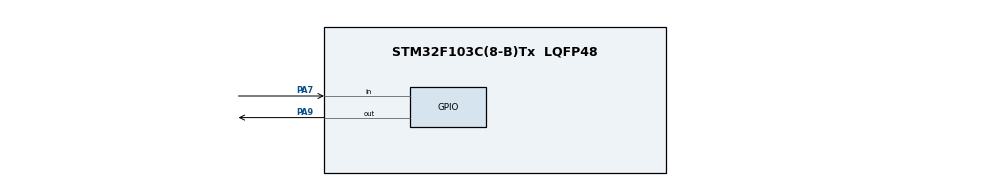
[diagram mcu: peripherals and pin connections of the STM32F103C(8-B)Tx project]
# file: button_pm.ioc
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Mcu.Family=STM32F1
Mcu.Name=STM32F103C(8-B)Tx
Mcu.Package=LQFP48
NVIC.PriorityGroup=NVIC_PRIORITYGROUP_4
NVIC.TIM1_UP_IRQn=true\:0\:0\:false\:false\:true\:true\:true\:true
NVIC.TIM2_IRQn=true\:0\:0\:false\:false\:true\:true\:true\:true
PA13.Mode=Serial_Wire
PA13.Signal=SYS_JTMS-SWDIO
PA14.Mode=Serial_Wire
PA14.Signal=SYS_JTCK-SWCLK
PA7.GPIO_PuPd=GPIO_PULLUP
PA7.Signal=GPIO_Input
PA9.Signal=GPIO_Output
ProjectManager.HeapSize=0x200
ProjectManager.StackSize=0x400
ProjectManager.TargetToolchain=MDK-ARM V5.32
RCC.APB1Freq_Value=8000000
RCC.APB2Freq_Value=8000000
TIM1.Period=9999
TIM1.Prescaler=79
TIM2.Period=999
TIM2.Prescaler=7
VP_TIM1_VS_ClockSourceINT.Mode=Internal
VP_TIM2_VS_ClockSourceINT.Mode=Internal
board=custom

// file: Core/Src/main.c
/* USER CODE BEGIN Header */
/**
  ******************************************************************************
  * @file           : main.c
  * @brief          : Main program body
  ******************************************************************************
  * @attention
  *
  * Copyright (c) 2026 STMicroelectronics.
  * All rights reserved.
  *
  * This software is licensed under terms that can be found in the LICENSE file
  * in the root directory of this software component.
  * If no LICENSE file comes with this software, it is provided AS-IS.
  *
  ******************************************************************************
  */
/* USER CODE END Header */
#include "main.h"

TIM_HandleTypeDef htim1;
TIM_HandleTypeDef htim2;

/* USER CODE BEGIN PV */
uint32_t state=0,blink=0,model=1;
/* USER CODE END PV */

void SystemClock_Config(void);
static void MX_GPIO_Init(void);
static void MX_TIM1_Init(void);
static void MX_TIM2_Init(void);

int main(void)
{

  /* MCU Configuration--------------------------------------------------------*/

  /* Reset of all peripherals, Initializes the Flash interface and the Systick. */
  HAL_Init();

  /* Configure the system clock */
  SystemClock_Config();

  /* Initialize all configured peripherals */
  MX_GPIO_Init();
  MX_TIM1_Init();
  MX_TIM2_Init();
  /* USER CODE BEGIN 2 */
 HAL_TIM_Base_Start_IT(&htim2);
  /* USER CODE END 2 */

  /* Infinite loop */
  /* USER CODE BEGIN WHILE */
  while (1)
  {
		if (model==1)
		{
			if (state==1)
			{
				HAL_GPIO_WritePin(GPIOA,GPIO_PIN_9,GPIO_PIN_SET);
			}
			else HAL_GPIO_WritePin(GPIOA,GPIO_PIN_9,GPIO_PIN_RESET);
		}
		else
		{
			if(blink==1)
			{
				HAL_TIM_Base_Start_IT(&htim1);
			}
			else
			{
				HAL_GPIO_WritePin(GPIOA,GPIO_PIN_9,GPIO_PIN_RESET);
				HAL_TIM_Base_Stop_IT(&htim1);
			}
		}
    /* USER CODE END WHILE */

  }
}

void SystemClock_Config(void)
{
  RCC_OscInitTypeDef RCC_OscInitStruct = {0};
  RCC_ClkInitTypeDef RCC_ClkInitStruct = {0};

  /** Initializes the RCC Oscillators according to the specified parameters
  * in the RCC_OscInitTypeDef structure.
  */
  RCC_OscInitStruct.OscillatorType = RCC_OSCILLATORTYPE_HSI;
  RCC_OscInitStruct.HSIState = RCC_HSI_ON;
  RCC_OscInitStruct.HSICalibrationValue = RCC_HSICALIBRATION_DEFAULT;
  RCC_OscInitStruct.PLL.PLLState = RCC_PLL_NONE;
  if (HAL_RCC_OscConfig(&RCC_OscInitStruct) != HAL_OK)
  {
    Error_Handler();
  }

  /** Initializes the CPU, AHB and APB buses clocks
  */
  RCC_ClkInitStruct.ClockType = RCC_CLOCKTYPE_HCLK|RCC_CLOCKTYPE_SYSCLK
                              |RCC_CLOCKTYPE_PCLK1|RCC_CLOCKTYPE_PCLK2;
  RCC_ClkInitStruct.SYSCLKSource = RCC_SYSCLKSOURCE_HSI;
  RCC_ClkInitStruct.AHBCLKDivider = RCC_SYSCLK_DIV1;
  RCC_ClkInitStruct.APB1CLKDivider = RCC_HCLK_DIV1;
  RCC_ClkInitStruct.APB2CLKDivider = RCC_HCLK_DIV1;

  if (HAL_RCC_ClockConfig(&RCC_ClkInitStruct, FLASH_LATENCY_0) != HAL_OK)
  {
    Error_Handler();
  }
}

static void MX_TIM1_Init(void)
{

  TIM_ClockConfigTypeDef sClockSourceConfig = {0};
  TIM_MasterConfigTypeDef sMasterConfig = {0};

  htim1.Instance = TIM1;
  htim1.Init.Prescaler = 79;
  htim1.Init.CounterMode = TIM_COUNTERMODE_UP;
  htim1.Init.Period = 9999;
  htim1.Init.ClockDivision = TIM_CLOCKDIVISION_DIV1;
  htim1.Init.RepetitionCounter = 0;
  htim1.Init.AutoReloadPreload = TIM_AUTORELOAD_PRELOAD_DISABLE;
  if (HAL_TIM_Base_Init(&htim1) != HAL_OK)
  {
    Error_Handler();
  }
  sClockSourceConfig.ClockSource = TIM_CLOCKSOURCE_INTERNAL;
  if (HAL_TIM_ConfigClockSource(&htim1, &sClockSourceConfig) != HAL_OK)
  {
    Error_Handler();
  }
  sMasterConfig.MasterOutputTrigger = TIM_TRGO_RESET;
  sMasterConfig.MasterSlaveMode = TIM_MASTERSLAVEMODE_DISABLE;
  if (HAL_TIMEx_MasterConfigSynchronization(&htim1, &sMasterConfig) != HAL_OK)
  {
    Error_Handler();
  }

}

static void MX_TIM2_Init(void)
{

  TIM_ClockConfigTypeDef sClockSourceConfig = {0};
  TIM_MasterConfigTypeDef sMasterConfig = {0};

  htim2.Instance = TIM2;
  htim2.Init.Prescaler = 7;
  htim2.Init.CounterMode = TIM_COUNTERMODE_UP;
  htim2.Init.Period = 999;
  htim2.Init.ClockDivision = TIM_CLOCKDIVISION_DIV1;
  htim2.Init.AutoReloadPreload = TIM_AUTORELOAD_PRELOAD_DISABLE;
  if (HAL_TIM_Base_Init(&htim2) != HAL_OK)
  {
    Error_Handler();
  }
  sClockSourceConfig.ClockSource = TIM_CLOCKSOURCE_INTERNAL;
  if (HAL_TIM_ConfigClockSource(&htim2, &sClockSourceConfig) != HAL_OK)
  {
    Error_Handler();
  }
  sMasterConfig.MasterOutputTrigger = TIM_TRGO_RESET;
  sMasterConfig.MasterSlaveMode = TIM_MASTERSLAVEMODE_DISABLE;
  if (HAL_TIMEx_MasterConfigSynchronization(&htim2, &sMasterConfig) != HAL_OK)
  {
    Error_Handler();
  }

}

static void MX_GPIO_Init(void)
{
  GPIO_InitTypeDef GPIO_InitStruct = {0};

  /* GPIO Ports Clock Enable */
  __HAL_RCC_GPIOA_CLK_ENABLE();

  /*Configure GPIO pin Output Level */
  HAL_GPIO_WritePin(GPIOA, GPIO_PIN_9, GPIO_PIN_RESET);

  /*Configure GPIO pin : PA7 */
  GPIO_InitStruct.Pin = GPIO_PIN_7;
  GPIO_InitStruct.Mode = GPIO_MODE_INPUT;
  GPIO_InitStruct.Pull = GPIO_PULLUP;
  HAL_GPIO_Init(GPIOA, &GPIO_InitStruct);

  /*Configure GPIO pin : PA9 */
  GPIO_InitStruct.Pin = GPIO_PIN_9;
  GPIO_InitStruct.Mode = GPIO_MODE_OUTPUT_PP;
  GPIO_InitStruct.Pull = GPIO_NOPULL;
  GPIO_InitStruct.Speed = GPIO_SPEED_FREQ_LOW;
  HAL_GPIO_Init(GPIOA, &GPIO_InitStruct);

}

/* USER CODE BEGIN 4 */
uint32_t count=0;
void HAL_TIM_PeriodElapsedCallback(TIM_HandleTypeDef *htim)
		{
       if(htim==&htim1)
			 {
				 HAL_GPIO_TogglePin(GPIOA,GPIO_PIN_9);
			 }
			 else if(htim==&htim2)
			 {
				 if(HAL_GPIO_ReadPin(GPIOA,GPIO_PIN_7)==0)
				 {
					 count++;
				 }
				 else
				 {
					 if(count>20 && count<1000 && blink!=1)
					 {
						 model=1;
						 state=!state;
					 }
					 else if(count>=1000)
           {
						 model=0;
             blink=!blink;
						 state=0;
					 }
					 count=0;
				 }
			 }
		}
/* USER CODE END 4 */

void Error_Handler(void)
{
  __disable_irq();
  while (1)
  {
  }
}
